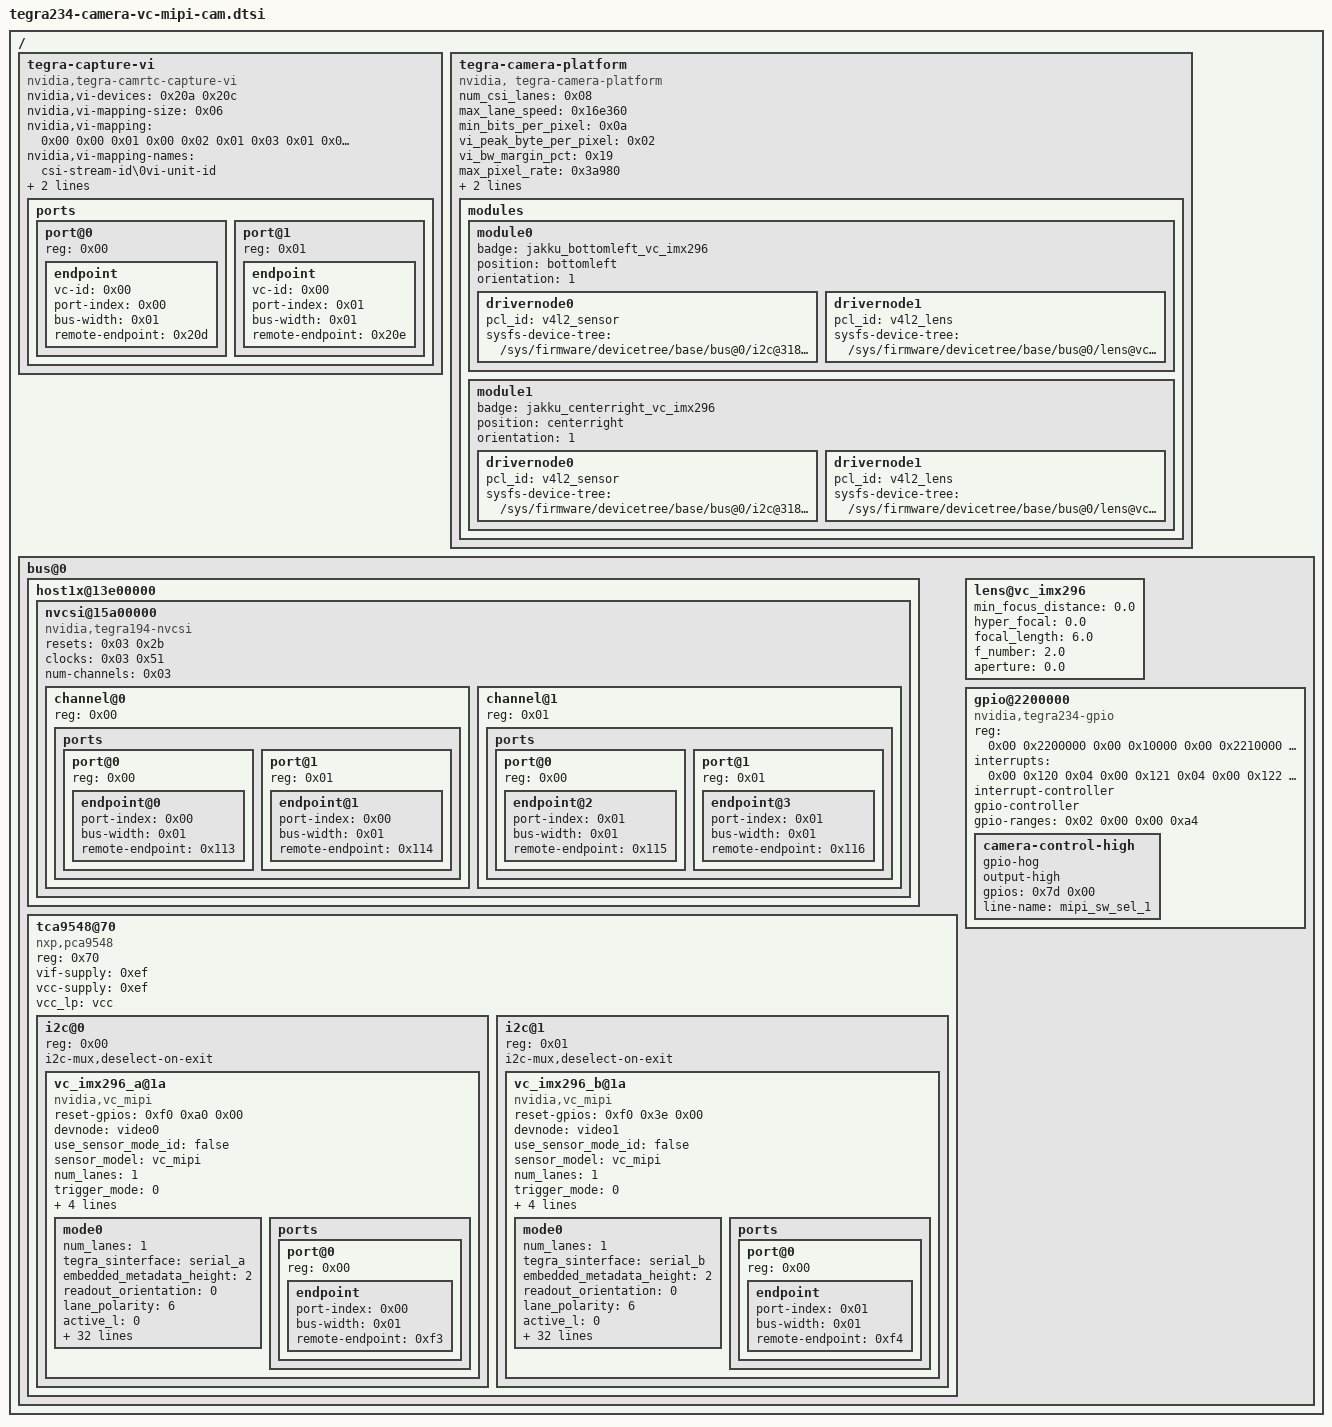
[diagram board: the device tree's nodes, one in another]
/{
	tegra-capture-vi {
		compatible = "nvidia,tegra-camrtc-capture-vi";
		nvidia,vi-devices = <0x20a 0x20c>;
		nvidia,vi-mapping-size = <0x06>;
		nvidia,vi-mapping = <0x00 0x00 0x01 0x00 0x02 0x01 0x03 0x01 0x04 0x00 0x05 0x01>;
		nvidia,vi-mapping-names = "csi-stream-id\0vi-unit-id";
		nvidia,vi-max-channels = <0x48>;
		status = "okay";
		num-channels = <0x03>; 
		phandle = <0x38a>;

		ports {
			#address-cells = <0x01>;
			#size-cells = <0x00>;
			status = "okay";
			port@0 {
				reg = <0x00>;
				status = "okay";

				endpoint {
					vc-id = <0x00>;
					port-index = <0x00>;
					status = "okay";
					bus-width = <0x01>;
					remote-endpoint = <0x20d>; 
				};
			};

			port@1 {
				status = "okay";
				reg = <0x01>;

				endpoint {
					vc-id = <0x00>;
					port-index = <0x01>;
					status = "okay";
					bus-width = <0x01>;
					remote-endpoint = <0x20e>; 
					phandle = <0x116>;
				};
			};

		};
	};

    
        
	tegra-camera-platform {
		compatible = "nvidia, tegra-camera-platform";
		status = "okay";
		num_csi_lanes = <0x08>;
		max_lane_speed = <0x16e360>;
		min_bits_per_pixel = <0x0a>;
		vi_peak_byte_per_pixel = <0x02>;
		vi_bw_margin_pct = <0x19>;
		max_pixel_rate = <0x3a980>;
		isp_peak_byte_per_pixel = <0x05>;
		isp_bw_margin_pct = <0x19>;
		phandle = <0x38b>;

		modules {  
			module0 {
				badge = "jakku_bottomleft_vc_imx296";
				position = "bottomleft";
				orientation = "1";
				status = "okay";

				drivernode0 {
					status = "okay";
					pcl_id = "v4l2_sensor";
					sysfs-device-tree = "/sys/firmware/devicetree/base/bus@0/i2c@3180000/tca9548@70/i2c@0/vc_imx296_a@1a";
				};

				drivernode1 {
					pcl_id = "v4l2_lens";
					sysfs-device-tree = "/sys/firmware/devicetree/base/bus@0/lens@vc_imx296";
				};
			};

			module1 {
				badge = "jakku_centerright_vc_imx296";
				position = "centerright";
				orientation = "1";
				status = "okay";

				drivernode0 {
					status = "okay";
					pcl_id = "v4l2_sensor";
					sysfs-device-tree = "/sys/firmware/devicetree/base/bus@0/i2c@3180000/tca9548@70/i2c@1/vc_imx296_b@1a";
				};

				drivernode1 {
					pcl_id = "v4l2_lens";
					sysfs-device-tree = "/sys/firmware/devicetree/base/bus@0/lens@vc_imx296";
				};
			};	
		};
	};

	bus@0 {
		host1x@13e00000 {
			nvcsi@15a00000 {                   
			compatible = "nvidia,tegra194-nvcsi";
			resets = <0x03 0x2b>;
			reset-names = "nvcsi";
			clocks = <0x03 0x51>;
			clock-names = "nvcsi";
			status = "okay";
			num-channels = <0x03>;  
			#address-cells = <0x01>;
			#size-cells = <0x00>;
			phandle = <0x264>;

			channel@0 {
				status = "okay";
				reg = <0x00>;

				ports {
					#address-cells = <0x01>;
					#size-cells = <0x00>;

					port@0 {
						status = "okay";
						reg = <0x00>;

						endpoint@0 {
							status = "okay";
							port-index = <0x00>;
							bus-width = <0x01>;
							remote-endpoint = <0x113>; 
							phandle = <0xf3>;
						};
					};

					port@1 {
						status = "okay";
						reg = <0x01>;

						endpoint@1 {
							status = "okay";
							port-index = <0x00>;
							bus-width = <0x01>;
							remote-endpoint = <0x114>;
							phandle = <0x20d>;
						};
					};
				};
			};

			channel@1 {
				status = "okay";
				reg = <0x01>;

				ports {
					#address-cells = <0x01>;
					#size-cells = <0x00>;

					port@0 {
						reg = <0x00>;
						status = "okay";

						endpoint@2 {
							status = "okay";
							port-index = <0x01>;
							bus-width = <0x01>;
							remote-endpoint = <0x115>;
							phandle = <0xf4>;
						};
					};

					port@1 {
						status = "okay";
						reg = <0x01>;

						endpoint@3 {
							status = "okay";
							port-index = <0x01>;
							bus-width = <0x01>;
							remote-endpoint = <0x116>;
							phandle = <0x20e>;
						};
					};
				};
			};

		};
	};
    
	tca9548@70 {
			compatible = "nxp,pca9548";
			reg = <0x70>;
			#address-cells = <0x01>;
			#size-cells = <0x00>;
			vif-supply = <0xef>;
			vcc-supply = <0xef>;
			vcc_lp = "vcc";
			i2c@0 {
				reg = <0x00>;
				i2c-mux,deselect-on-exit;

				vc_imx296_a@1a {
					status = "okay";
					reset-gpios = <0xf0 0xa0 0x00>;
					devnode = "video0";
					compatible = "nvidia,vc_mipi";
					use_sensor_mode_id = "false";
					sensor_model = "vc_mipi";
					num_lanes = "1";
					trigger_mode = "0";
					io_mode = "1";
					physical_w = "4.968";
					physical_h = "3.726";
					reg = <0x1a>;

					mode0 {
						num_lanes = "1";
						tegra_sinterface = "serial_a";
						embedded_metadata_height = "2";
						readout_orientation = "0";
						lane_polarity = "6";
						active_l = "0";
						active_t = "0";
						active_w = "1440";
						active_h = "1080";
						mode_type = "bayer";
						pixel_phase = "rggb";
						csi_pixel_bit_depth = "10";
						min_gain_val = "0";
						max_gain_val = "48000";
						step_gain_val = "100";
						default_gain = "0";
						min_exp_time = "1";
						max_exp_time = "1000000";
						step_exp_time = "1";
						default_exp_time = "10000";
						min_framerate = "100";
						max_framerate = "60000";
						step_framerate = "100";
						default_framerate = "60000";
						gain_factor = "1000";
						exposure_factor = "1000000";
						framerate_factor = "1000";
						inherent_gain = "1";
						min_hdr_ratio = "1";
						max_hdr_ratio = "1";
						line_length = "0";
						phy_mode = "DPHY";
						discontinuous_clk = "no";
						mclk_khz = "24000";
						pix_clk_hz = "150000000";
						mclk_multiplier = "0.0";
						cil_settletime = "0";
						dpcm_enable = "false";
					};

					ports {
						#address-cells = <0x01>;
						#size-cells = <0x00>;

						port@0 {
							reg = <0x00>;

							endpoint {
								status = "okay";
								port-index = <0x00>;
								bus-width = <0x01>;
								remote-endpoint = <0xf3>;
								phandle = <0x113>;
							};
						};
					};
				};
			};

			i2c@1 {
				reg = <0x01>;
				i2c-mux,deselect-on-exit;

				vc_imx296_b@1a {
					status = "okay";
					reset-gpios = <0xf0 0x3e 0x00>;
					devnode = "video1";
					compatible = "nvidia,vc_mipi";
					use_sensor_mode_id = "false";
					sensor_model = "vc_mipi";
					num_lanes = "1";
					trigger_mode = "0";
					io_mode = "1";
					physical_w = "4.968";
					physical_h = "3.726";
					reg = <0x1a>;

					mode0 {
						num_lanes = "1";
						tegra_sinterface = "serial_b";
						embedded_metadata_height = "2";
						readout_orientation = "0";
						lane_polarity = "6";
						active_l = "0";
						active_t = "0";
						active_w = "1440";
						active_h = "1080";
						mode_type = "bayer";
						pixel_phase = "rggb";
						csi_pixel_bit_depth = "10";
						min_gain_val = "0";
						max_gain_val = "48000";
						step_gain_val = "100";
						default_gain = "0";
						min_exp_time = "1";
						max_exp_time = "1000000";
						step_exp_time = "1";
						default_exp_time = "10000";
						min_framerate = "100";
						max_framerate = "60000";
						step_framerate = "100";
						default_framerate = "60000";
						gain_factor = "1000";
						exposure_factor = "1000000";
						framerate_factor = "1000";
						inherent_gain = "1";
						min_hdr_ratio = "1";
						max_hdr_ratio = "1";
						line_length = "0";
						phy_mode = "DPHY";
						discontinuous_clk = "no";
						mclk_khz = "24000";
						pix_clk_hz = "150000000";
						mclk_multiplier = "0.0";
						cil_settletime = "0";
						dpcm_enable = "false";
					};

					ports {
						#address-cells = <0x01>;
						#size-cells = <0x00>;

						port@0 {
							reg = <0x00>;

							endpoint {
								status = "okay";
								port-index = <0x01>;
								bus-width = <0x01>;
								remote-endpoint = <0xf4>;
								phandle = <0x115>;
							};
						};
					};
				};
			};	
	};
	lens@vc_imx296 {
			min_focus_distance = "0.0";
			hyper_focal = "0.0";
			focal_length = "6.0";
			f_number = "2.0";
			aperture = "0.0";
		};
        
gpio@2200000 {
		compatible = "nvidia,tegra234-gpio";
		reg-names = "security\0gpio";
		reg = <0x00 0x2200000 0x00 0x10000 0x00 0x2210000 0x00 0x10000>;
		interrupts = <0x00 0x120 0x04 0x00 0x121 0x04 0x00 0x122 0x04 0x00 0x123 0x04 0x00 0x124 0x04 0x00 0x125 0x04 0x00 0x126 0x04 0x00 0x127 0x04 0x00 0x128 0x04 0x00 0x129 0x04 0x00 0x12a 0x04 0x00 0x12b 0x04 0x00 0x12c 0x04 0x00 0x12d 0x04 0x00 0x12e 0x04 0x00 0x12f 0x04 0x00 0x130 0x04 0x00 0x131 0x04 0x00 0x132 0x04 0x00 0x133 0x04 0x00 0x134 0x04 0x00 0x135 0x04 0x00 0x136 0x04 0x00 0x137 0x04 0x00 0x138 0x04 0x00 0x139 0x04 0x00 0x13a 0x04 0x00 0x13b 0x04 0x00 0x13c 0x04 0x00 0x13d 0x04 0x00 0x13e 0x04 0x00 0x13f 0x04 0x00 0x140 0x04 0x00 0x141 0x04 0x00 0x142 0x04 0x00 0x143 0x04 0x00 0x144 0x04 0x00 0x145 0x04 0x00 0x146 0x04 0x00 0x147 0x04 0x00 0x148 0x04 0x00 0x149 0x04 0x00 0x14a 0x04 0x00 0x14b 0x04 0x00 0x14c 0x04 0x00 0x14d 0x04 0x00 0x14e 0x04 0x00 0x14f 0x04>;
		#interrupt-cells = <0x02>;
		interrupt-controller;
		#gpio-cells = <0x02>;
		gpio-controller;
		gpio-ranges = <0x02 0x00 0x00 0xa4>;
		status = "okay";
		phandle = <0xf0>;

		camera-control-high {
			gpio-hog;
			output-high;
			gpios = <0x7d 0x00>;
			line-name = "mipi_sw_sel_1";
			status = "okay";
		};
	};

	
	};



__symbols__ {
    gpio = "/bus@0/gpio@2200000";
    gpio_aon = "/bus@0/gpio@c2f0000";
    cam_i2c = "/bus@0/i2c@3180000";
    vi_out0 = "/bus@0/i2c@3180000/tca9548@70/i2c@0/vc_imx296_a@1a/ports/port@0/endpoint";
    vi_out1 = "/bus@0/i2c@3180000/tca9548@70/i2c@1/vc_imx296_b@1a/ports/port@0/endpoint";
    vi_out2 = "/bus@0/i2c@3180000/tca9548@70/i2c@2/vc_imx296_c@1a/ports/port@0/endpoint";
    vi_out3 = "/bus@0/i2c@3180000/tca9548@70/i2c@3/vc_imx296_d@1a/ports/port@0/endpoint";
    nvcsi = "/bus@0/host1x@13e00000/nvcsi@15a00000";
	csi_in0 = "/bus@0/host1x@13e00000/nvcsi@15a00000/channel@0/ports/port@0/endpoint@0";
	csi_out0 = "/bus@0/host1x@13e00000/nvcsi@15a00000/channel@0/ports/port@1/endpoint@1";
	csi_in1 = "/bus@0/host1x@13e00000/nvcsi@15a00000/channel@1/ports/port@0/endpoint@2";
	csi_out1 = "/bus@0/host1x@13e00000/nvcsi@15a00000/channel@1/ports/port@1/endpoint@3";
	csi_in2 = "/bus@0/host1x@13e00000/nvcsi@15a00000/channel@2/ports/port@0/endpoint@4";
	csi_out2 = "/bus@0/host1x@13e00000/nvcsi@15a00000/channel@2/ports/port@1/endpoint@5";
	csi_in3 = "/bus@0/host1x@13e00000/nvcsi@15a00000/channel@3/ports/port@0/endpoint@6";
	csi_out3 = "/bus@0/host1x@13e00000/nvcsi@15a00000/channel@3/ports/port@1/endpoint@7";
    capture_vi = "/tegra-capture-vi";
    vi_in0 = "/tegra-capture-vi/ports/port@0/endpoint";
    vi_in1 = "/tegra-capture-vi/ports/port@1/endpoint";
    vi_in2 = "/tegra-capture-vi/ports/port@2/endpoint";
    vi_in3 = "/tegra-capture-vi/ports/port@3/endpoint";
    tcp = "/tegra-camera-platform";
    };
    
};
